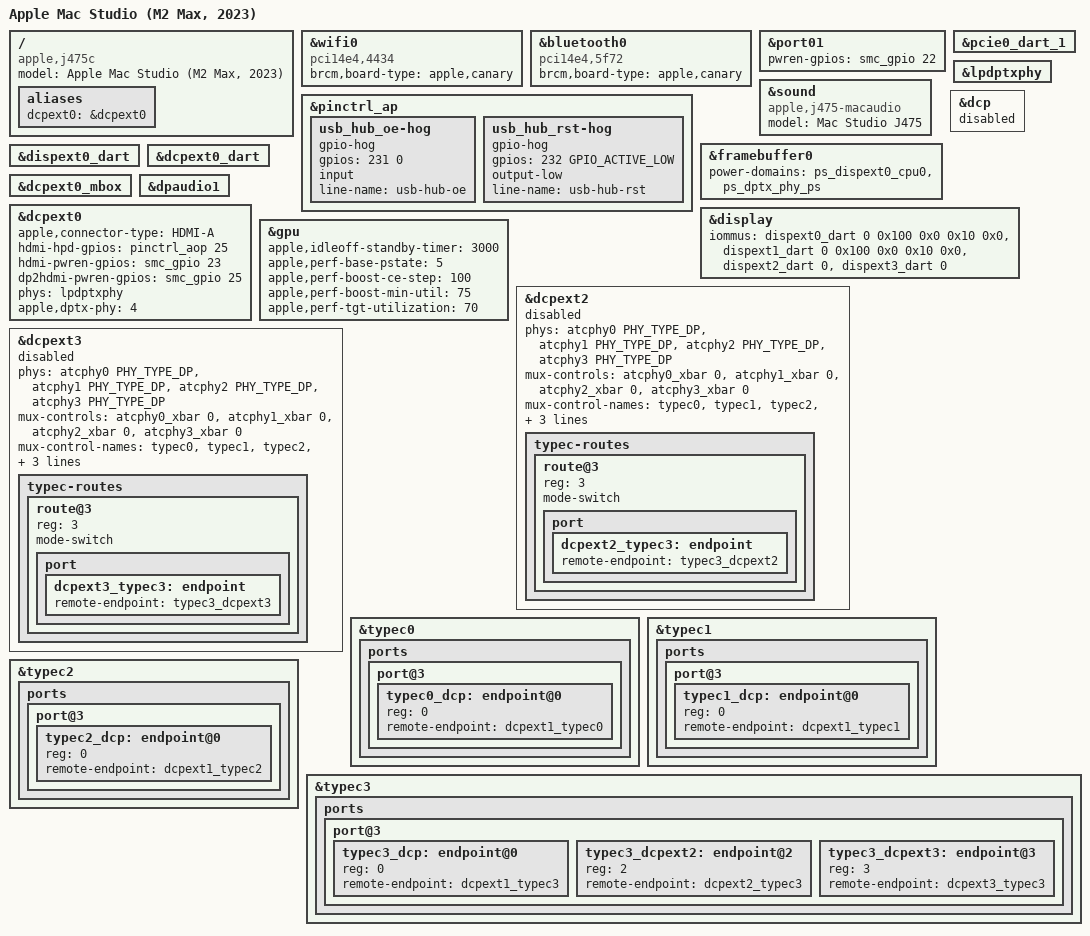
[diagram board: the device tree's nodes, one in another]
// SPDX-License-Identifier: GPL-2.0+ OR MIT
/*
 * Mac Studio (M2 Max, 2023)
 *
 * target-type: J475c
 *
 * Copyright The Asahi Linux Contributors
 */

/dts-v1/;

#include "t6021.dtsi"
#include "t602x-j474-j475.dtsi"

/ {
	compatible = "apple,j475c", "apple,t6021", "apple,arm-platform";
	model = "Apple Mac Studio (M2 Max, 2023)";
};

&wifi0 {
	compatible = "pci14e4,4434";
	brcm,board-type = "apple,canary";
};

&bluetooth0 {
	compatible = "pci14e4,5f72";
	brcm,board-type = "apple,canary";
};

/* enable PCIe port01 with SDHCI */
&port01 {
	pwren-gpios = <&smc_gpio 22 GPIO_ACTIVE_HIGH>;
	status = "okay";
};

&pcie0_dart_1 {
	status = "okay";
};

&pinctrl_ap {
	usb_hub_oe-hog {
		gpio-hog;
		gpios = <231 0>;
		input;
		line-name = "usb-hub-oe";
	};

	usb_hub_rst-hog {
		gpio-hog;
		gpios = <232 GPIO_ACTIVE_LOW>;
		output-low;
		line-name = "usb-hub-rst";
	};
};

&sound {
	compatible = "apple,j475-macaudio", "apple,j375-macaudio", "apple,macaudio";
	model = "Mac Studio J475";
};

&lpdptxphy {
	status = "okay";
};


#define USE_DCPEXT0 1

#if USE_DCPEXT0
/ {
	aliases {
		dcpext0 = &dcpext0;
		/delete-property/ dcp;
	};
};

&framebuffer0 {
	power-domains = <&ps_dispext0_cpu0>, <&ps_dptx_phy_ps>;
};

&dcp {
	status = "disabled";
};
&display {
	iommus = <&dispext0_dart 0 0x100 0x0 0x10 0x0>, <&dispext1_dart 0 0x100 0x0 0x10 0x0>;
};
&dispext0_dart {
	status = "okay";
};
&dcpext0_dart {
	status = "okay";
};
&dcpext0_mbox {
	status = "okay";
};
&dpaudio1 {
	status = "okay";
};
&dcpext0 {
#else
&dpaudio0 {
	status = "okay";
};
&dcp {
#endif
	status = "okay";
	apple,connector-type = "HDMI-A";

	/*  HDMI HPD gpio, used as interrupt*/
	hdmi-hpd-gpios = <&pinctrl_aop 25 GPIO_ACTIVE_HIGH>;

	hdmi-pwren-gpios = <&smc_gpio 23 GPIO_ACTIVE_HIGH>;
	dp2hdmi-pwren-gpios = <&smc_gpio 25 GPIO_ACTIVE_HIGH>;

	phys = <&lpdptxphy>;
	phy-names = "dp-phy";
	apple,dptx-phy = <4>;
};

&gpu {
	apple,idleoff-standby-timer = <3000>;
	apple,perf-base-pstate = <5>;
	apple,perf-boost-ce-step = <100>;
	apple,perf-boost-min-util = <75>;
	apple,perf-tgt-utilization = <70>;
};

#include "hwmon-fan-dual.dtsi"

/*
 * Three independent outputs: two more external display pipes, dcpext2 and
 * dcpext3, from the M2 Max laptops (t6021-display2.dtsi). Their addresses,
 * interrupts and DARTs match this Studio's ADT. On the Studio they can
 * drive any of the four rear USB-C ports (ATC0-3) through the per-ATC
 * display crossbar; HDMI stays on dcpext0 (lpdptx-phy0).
 * HDMI + up to three rear USB-C screens, or three USB-C screens.
 */
#include "t6021-display2.dtsi"

/* display2 lists disp0_dart; dcp (and its DART) stays off here. */
&display {
	iommus = <&dispext0_dart 0 0x100 0x0 0x10 0x0>,
		 <&dispext1_dart 0 0x100 0x0 0x10 0x0>,
		 <&dispext2_dart 0>, <&dispext3_dart 0>;
};

/*
 * Disabled until m1n1 (dt_reserve_dcpext_firmware) reserves the firmware
 * and sets apple,firmware-compat and status "okay" for each dcpextN alias
 * whose IOP exists. A dcpext that is "okay" but cannot probe would keep
 * the Type-C muxes from registering and take every rear USB-C port (and
 * the DRM device) down with it.
 */
&dcpext2 {
	status = "disabled";
	phys = <&atcphy0 PHY_TYPE_DP>, <&atcphy1 PHY_TYPE_DP>,
	       <&atcphy2 PHY_TYPE_DP>, <&atcphy3 PHY_TYPE_DP>;
	phy-names = "typec0", "typec1", "typec2", "typec3";
	mux-controls = <&atcphy0_xbar 0>, <&atcphy1_xbar 0>,
		       <&atcphy2_xbar 0>, <&atcphy3_xbar 0>;
	mux-control-names = "typec0", "typec1", "typec2", "typec3";
	apple,typec-mux-indices = <4 4 4 4>;
	apple,typec-dptx-phys = <0 1 2 3>;

	typec-routes {
		route@3 {
			reg = <3>;
			mode-switch;
			port {
				dcpext2_typec3: endpoint {
					remote-endpoint = <&typec3_dcpext2>;
				};
			};
		};
	};
};

&dcpext3 {
	status = "disabled";
	phys = <&atcphy0 PHY_TYPE_DP>, <&atcphy1 PHY_TYPE_DP>,
	       <&atcphy2 PHY_TYPE_DP>, <&atcphy3 PHY_TYPE_DP>;
	phy-names = "typec0", "typec1", "typec2", "typec3";
	mux-controls = <&atcphy0_xbar 0>, <&atcphy1_xbar 0>,
		       <&atcphy2_xbar 0>, <&atcphy3_xbar 0>;
	mux-control-names = "typec0", "typec1", "typec2", "typec3";
	apple,typec-mux-indices = <6 6 6 6>;
	apple,typec-dptx-phys = <0 1 2 3>;

	typec-routes {
		route@3 {
			reg = <3>;
			mode-switch;
			port {
				dcpext3_typec3: endpoint {
					remote-endpoint = <&typec3_dcpext3>;
				};
			};
		};
	};
};

/*
 * port@3 of each rear port now has three endpoints (dcpext1, 2, 3): make it
 * addressable and give the dcpext1 endpoint unit 0, as the laptops do.
 */
&typec0 {
	ports {
		port@3 {
			#address-cells = <1>;
			#size-cells = <0>;
			/delete-node/ endpoint;
			typec0_dcp: endpoint@0 {
				reg = <0>;
				remote-endpoint = <&dcpext1_typec0>;
			};
		};
	};
};

&typec1 {
	ports {
		port@3 {
			#address-cells = <1>;
			#size-cells = <0>;
			/delete-node/ endpoint;
			typec1_dcp: endpoint@0 {
				reg = <0>;
				remote-endpoint = <&dcpext1_typec1>;
			};
		};
	};
};

&typec2 {
	ports {
		port@3 {
			#address-cells = <1>;
			#size-cells = <0>;
			/delete-node/ endpoint;
			typec2_dcp: endpoint@0 {
				reg = <0>;
				remote-endpoint = <&dcpext1_typec2>;
			};
		};
	};
};

&typec3 {
	ports {
		port@3 {
			#address-cells = <1>;
			#size-cells = <0>;
			/delete-node/ endpoint;
			typec3_dcp: endpoint@0 {
				reg = <0>;
				remote-endpoint = <&dcpext1_typec3>;
			};
			typec3_dcpext2: endpoint@2 {
				reg = <2>;
				remote-endpoint = <&dcpext2_typec3>;
			};
			typec3_dcpext3: endpoint@3 {
				reg = <3>;
				remote-endpoint = <&dcpext3_typec3>;
			};
		};
	};
};
